VERSION ""

NS_ :

BS_:

BU_: ABS ECM BCM IC

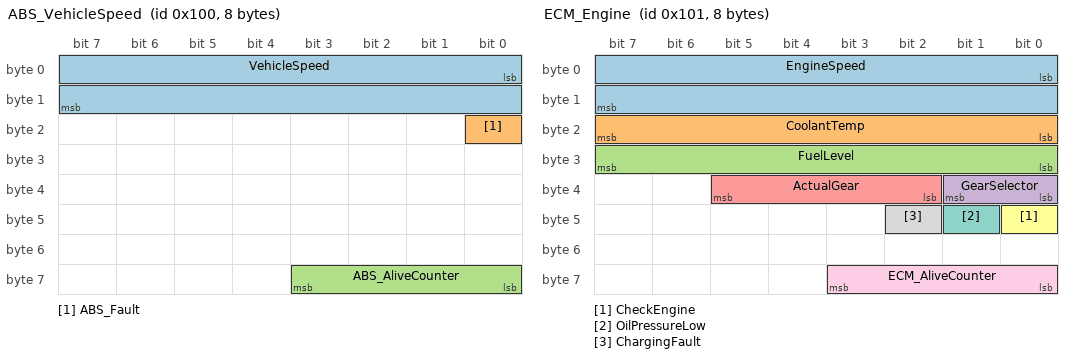
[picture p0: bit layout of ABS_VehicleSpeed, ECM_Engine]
BO_ 256 ABS_VehicleSpeed: 8 ABS
 SG_ VehicleSpeed : 0|16@1+ (0.01,0) [0|300] "km/h" IC
 SG_ ABS_Fault : 16|1@1+ (1,0) [0|1] "" IC
 SG_ ABS_AliveCounter : 56|4@1+ (1,0) [0|15] "" IC

BO_ 257 ECM_Engine: 8 ECM
 SG_ EngineSpeed : 0|16@1+ (0.25,0) [0|16383.75] "rpm" IC
 SG_ CoolantTemp : 16|8@1+ (1,-40) [-40|215] "degC" IC
 SG_ FuelLevel : 24|8@1+ (0.5,0) [0|100] "%" IC
 SG_ GearSelector : 32|2@1+ (1,0) [0|3] "" IC
 SG_ ActualGear : 34|4@1+ (1,0) [0|8] "" IC
 SG_ CheckEngine : 40|1@1+ (1,0) [0|1] "" IC
 SG_ OilPressureLow : 41|1@1+ (1,0) [0|1] "" IC
 SG_ ChargingFault : 42|1@1+ (1,0) [0|1] "" IC
 SG_ ECM_AliveCounter : 56|4@1+ (1,0) [0|15] "" IC

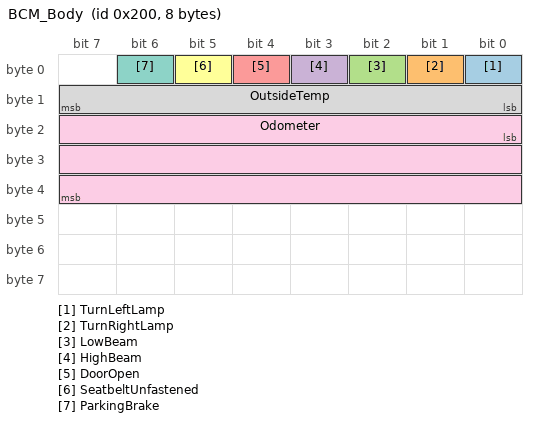
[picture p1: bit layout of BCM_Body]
BO_ 512 BCM_Body: 8 BCM
 SG_ TurnLeftLamp : 0|1@1+ (1,0) [0|1] "" IC
 SG_ TurnRightLamp : 1|1@1+ (1,0) [0|1] "" IC
 SG_ LowBeam : 2|1@1+ (1,0) [0|1] "" IC
 SG_ HighBeam : 3|1@1+ (1,0) [0|1] "" IC
 SG_ DoorOpen : 4|1@1+ (1,0) [0|1] "" IC
 SG_ SeatbeltUnfastened : 5|1@1+ (1,0) [0|1] "" IC
 SG_ ParkingBrake : 6|1@1+ (1,0) [0|1] "" IC
 SG_ OutsideTemp : 8|8@1+ (0.5,-40) [-40|87.5] "degC" IC
 SG_ Odometer : 16|24@1+ (0.1,0) [0|1677721.5] "km" IC

CM_ BO_ 256 "Wheel-based vehicle speed from the ABS/ESC ECU. Cycle 20 ms.";
CM_ BO_ 257 "Engine and transmission status from the engine ECU. Cycle 20 ms.";
CM_ BO_ 512 "Body status (lamps, doors, belts) from the body control module. Cycle 100 ms.";
CM_ SG_ 256 ABS_AliveCounter "Rolling counter 0..15, incremented every frame.";
CM_ SG_ 257 ECM_AliveCounter "Rolling counter 0..15, incremented every frame.";
CM_ SG_ 257 ActualGear "Engaged gear of the automatic gearbox, 0 = none.";
CM_ SG_ 512 TurnLeftLamp "Flashing lamp state as driven by the BCM (about 85 flashes/min).";
CM_ SG_ 512 TurnRightLamp "Flashing lamp state as driven by the BCM (about 85 flashes/min).";

VAL_ 257 GearSelector 0 "P" 1 "R" 2 "N" 3 "D" ;
